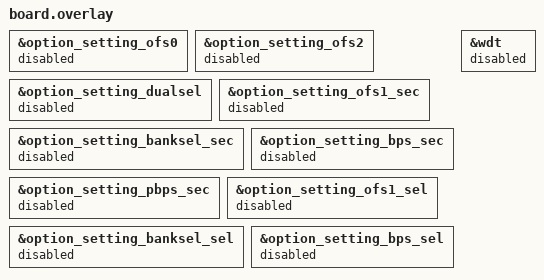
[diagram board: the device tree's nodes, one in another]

/* Disable OFS (Option Function Select) nodes so their high-address
 * sections don't end up in the app HEX.  MCUboot's own build still
 * has them, so the merged HEX programs OFS correctly.
 */
&option_setting_ofs0        { status = "disabled"; };
&option_setting_ofs2        { status = "disabled"; };
&option_setting_dualsel     { status = "disabled"; };
&option_setting_ofs1_sec    { status = "disabled"; };
&option_setting_banksel_sec { status = "disabled"; };
&option_setting_bps_sec     { status = "disabled"; };
&option_setting_pbps_sec    { status = "disabled"; };
&option_setting_ofs1_sel    { status = "disabled"; };
&option_setting_banksel_sel { status = "disabled"; };
&option_setting_bps_sel     { status = "disabled"; };

/* The RA WDT driver (r_wdt.c) doesn't build for RA8D1 either: it needs
 * BSP_CFG_OPTION_SETTING_OFS0, which the RA8D1 BSP config doesn't define.
 * Disable the wdt node so the driver isn't enabled and the watchdog module
 * stays off. */
&wdt { status = "disabled"; };

#include "../../../app.overlay"
